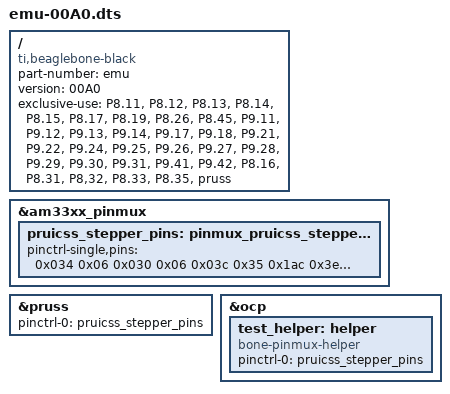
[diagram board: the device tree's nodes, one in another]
/dts-v1/;
/plugin/;

/ {
    compatible = "ti,beaglebone-black",  "ti,beaglebone-green";

    /* identification */
    part-number = "emu";

    /* version */
    version = "00A0";

    /* state the resources this cape uses or prepare to get winged! */
    exclusive-use =
        /* the pin header P9 uses */
        "P8.11",
        "P8.12",
        "P8.13",
        "P8.14",
        "P8.15",
        "P8.17",
        "P8.19",
        "P8.26",
        "P8.45",
        "P9.11",
        "P9.12",
        "P9.13",
        "P9.14",
        "P9.17",
        "P9.18",
        "P9.21",
        "P9.22",
        "P9.24",
        "P9.25",
        "P9.26",
        "P9.27",
        "P9.28",
        "P9.29",
        "P9.30",
        "P9.31",
        "P9.41",
        "P9.42",
        /* Rev B Pins */
        "P8.16",
        "P8.31",
        "P8,32",
        "P8.33",
        "P8.35",
        /* Hardware IP cores in use */
        "pruss"; 

    fragment@0 {
        target = <&am33xx_pinmux>;
        __overlay__ {
            pruicss_stepper_pins: pinmux_pruicss_stepper_pins{
                pinctrl-single,pins = <
                     // All inputs pullup
                     // All outputs fast pullup disabled
                     // These go to PRU0
                    0x034 0x06 // OUT P8_11 = pr1_pru0_pru_30_15
                    0x030 0x06 // OUT P8_12 = pr1_pru0_pru_30_14
                    0x03c 0x35 // IN/OUT P8_15 = pr1_ecap0 pullup input fast
                    0x1ac 0x3e // IN  P9_25 = pr1_pru0_pru_30_7
                    0x1a4 0x05 // OUT P9_27 = pr1_pru0_pru_31_5
                    0x19c 0x05 // OUT P9_28 = pr1_pru0_pru_31_3
                    0x194 0x05 // OUT P9_29 = pr1_pru0_pru_31_1
                    0x198 0x05 // OUT P9_30 = pr1_pru0_pru_31_2
                    0x190 0x3e // IN  P9_31 = pr1_pru0_pru_30_0
                    0x1a8 0x3e // IN  P9_41 = pr1_pru0_pru_30_6
                    0x1a0 0x05 // OUT  P9_42.1 = pr1_pru0_pru_31_4
                    // Timing testing from PRU1
                    0xa0 0x05 // OUT  P8_45 = pr1_pru1_pru_30_0


                     // These are GPIO
                    0x15C 0x3f // IN   P9_17 = gpio0_5
                    0x158 0x3f // IN   P9_18 = gpio0_4
                    0x150 0x3f // IN   P9_22 = gpio0_2
                    0x154 0x3f // IN   P9_21 = gpio0_3
                    0x020 0x3f // IN   P8_19 = gpio0_22
                    0x024 0x37 // IN   P8_13 = gpio0_23, pullup
                    0x028 0x3f // IN   P8_14 = gpio0_26
                    0x02c 0x3f // IN   P8_17 = gpio0_27
                    0x070 0x0f // OUT  P9_11 = gpio0_30
                    0x078 0x0f // OUT  P9_12 = gpio1_28
                    0x074 0x0f // OUT  P9_13 = gpio0_31
                    0x040 0x0f // OUT  P9_15 = gpio1_16
                    0x184 0x0f // OUT  P9_24 = gpio0_15
                    0x180 0x0f // OUT  P9_26 = gpio0_14
                    0x07c 0x37 // IN   P8_26 = gpio1_29, pullup, REV C detect
                    // Rev B GPIO
                    0x038 0x37 // IN   P8_16 = gpio1_14, pullup
                    0x0d8 0x3f // IN   P8_31 = gpio0_10
                    0x0dc 0x3f // IN   P8_32 = gpio0_11
                    0x0d4 0x3f // IN   P8_33 = gpio0_09
                    0x0d0 0x3f // IN   P8_35 = gpio0_08
                >;
            };        

        };
    };

    fragment@1{
        target = <&pruss>;
        __overlay__{
            status = "okay";
            pinctrl-names = "default";
            pinctrl-0       = <&pruicss_stepper_pins>;

        };
    };
    fragment@2 {
        target = <&ocp>;
        __overlay__ {
            test_helper: helper {
                compatible = "bone-pinmux-helper";
                pinctrl-names = "default";
                pinctrl-0 = <&pruicss_stepper_pins>;
                status = "okay";
            };
        };
   };
};
